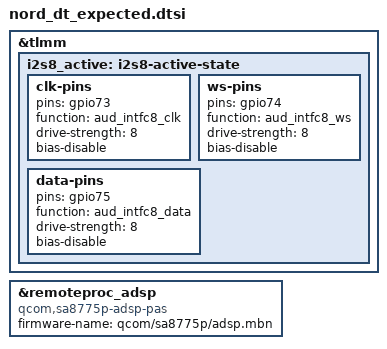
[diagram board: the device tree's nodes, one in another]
/*
 * Generated by Phase-2B WP3 dt_scaffolding.
 * Deterministic. No timestamps.
 */

&tlmm {
	i2s8_active: i2s8-active-state {
		clk-pins {
			pins = "gpio73";
			function = "aud_intfc8_clk";
			drive-strength = <8>;
			bias-disable;
		};

		ws-pins {
			pins = "gpio74";
			function = "aud_intfc8_ws";
			drive-strength = <8>;
			bias-disable;
		};

		data-pins {
			pins = "gpio75";
			function = "aud_intfc8_data";
			drive-strength = <8>;
			bias-disable;
		};
	};
};

&remoteproc_adsp {
	compatible = "qcom,sa8775p-adsp-pas";
	firmware-name = "qcom/sa8775p/adsp.mbn";
};
